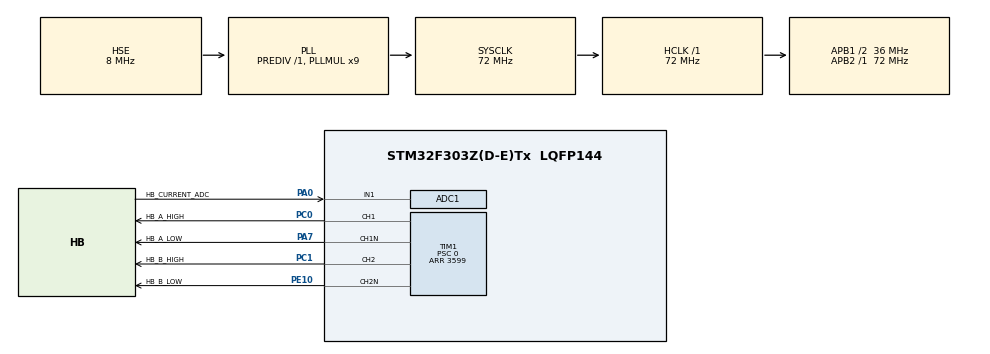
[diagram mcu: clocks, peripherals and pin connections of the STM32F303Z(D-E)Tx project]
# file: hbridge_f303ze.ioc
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# Reconstructed STM32F303ZE H-bridge profile. CubeMX GUI Generate Code has not been run.
# The checked-in HAL initialization and ARM ELF build are verified separately.
# PC0/PA7=left high/low; PC1/PE10=right high/low; PA0=current ADC.
# Driver EN is tied high on the supplied PCB. Do not add a fictional EN GPIO.
ADC1.Channel-0\#ChannelRegularConversion=ADC_CHANNEL_1
ADC1.ClockPrescaler=ADC_CLOCK_SYNC_PCLK_DIV2
ADC1.ContinuousConvMode=DISABLE
ADC1.DMAContinuousRequests=DISABLE
ADC1.DataAlign=ADC_DATAALIGN_RIGHT
ADC1.DiscontinuousConvMode=DISABLE
ADC1.EOCSelection=ADC_EOC_SINGLE_CONV
ADC1.ExternalTrigConv=ADC_EXTERNALTRIGCONV_T1_TRGO
ADC1.ExternalTrigConvEdge=ADC_EXTERNALTRIGCONVEDGE_RISING
ADC1.LowPowerAutoWait=DISABLE
ADC1.NbrOfConversion=1
ADC1.NbrOfConversionFlag=1
ADC1.Offset-0\#ChannelRegularConversion=0
ADC1.OffsetNumber-0\#ChannelRegularConversion=ADC_OFFSET_NONE
ADC1.Overrun=ADC_OVR_DATA_PRESERVED
ADC1.Rank-0\#ChannelRegularConversion=1
ADC1.Resolution=ADC_RESOLUTION_12B
ADC1.SamplingTime-0\#ChannelRegularConversion=ADC_SAMPLETIME_19CYCLES_5
ADC1.ScanConvMode=ADC_SCAN_DISABLE
ADC1.master=1
Mcu.Family=STM32F3
Mcu.Name=STM32F303Z(D-E)Tx
Mcu.Package=LQFP144
NVIC.ADC1_2_IRQn=true\:1\:0\:false\:false\:true\:true\:true\:true
NVIC.PriorityGroup=NVIC_PRIORITYGROUP_4
PA0.GPIO_Label=HB_CURRENT_ADC
PA0.Mode=IN1-Single-Ended
PA0.Signal=ADC1_IN1
PA13.Mode=Serial_Wire
PA13.Signal=SYS_JTMS-SWDIO
PA14.Mode=Serial_Wire
PA14.Signal=SYS_JTCK-SWCLK
PF0-OSC_IN.Mode=HSE-External-Clock-Source
PF0-OSC_IN.Signal=RCC_OSC_IN
ProjectManager.HeapSize=0x0
ProjectManager.StackSize=0x1000
ProjectManager.TargetToolchain=STM32CubeIDE
RCC.AHBFreq_Value=72000000
RCC.APB1CLKDivider=RCC_HCLK_DIV2
RCC.APB1Freq_Value=36000000
RCC.APB1TimFreq_Value=72000000
RCC.APB2Freq_Value=72000000
RCC.APB2CLKDivider=RCC_HCLK_DIV1
RCC.APB2TimFreq_Value=72000000
RCC.CortexFreq_Value=72000000
RCC.HCLKFreq_Value=72000000
RCC.HSE_VALUE=8000000
RCC.HSI_VALUE=8000000
RCC.PLLMUL=RCC_PLL_MUL9
RCC.PLLSourceVirtual=RCC_PLLSOURCE_HSE
RCC.PREDIV=RCC_PREDIV_DIV1
RCC.SYSCLKFreq_VALUE=72000000
RCC.SYSCLKSourceVirtual=RCC_SYSCLKSOURCE_PLLCLK
RCC.TIM1SW=RCC_TIM1CLK_HCLK
TIM1.AutoReloadPreload=TIM_AUTORELOAD_PRELOAD_ENABLE
TIM1.AutomaticOutput=TIM_AUTOMATICOUTPUT_DISABLE
TIM1.Break2Filter=0
TIM1.Break2Polarity=TIM_BREAK2POLARITY_HIGH
TIM1.Break2State=TIM_BREAK2_DISABLE
TIM1.BreakFilter=0
TIM1.BreakPolarity=TIM_BREAKPOLARITY_HIGH
TIM1.BreakState=TIM_BREAK_DISABLE
TIM1.ClockDivision=TIM_CLOCKDIVISION_DIV1
TIM1.CounterMode=TIM_COUNTERMODE_UP
TIM1.DeadTime=72
TIM1.LockLevel=TIM_LOCKLEVEL_OFF
TIM1.OffStateIDLEMode=TIM_OSSI_ENABLE
TIM1.OffStateRunMode=TIM_OSSR_ENABLE
TIM1.Period=3599
TIM1.Prescaler=0
TIM1.RepetitionCounter=0
TIM1.TIM_MasterOutputTrigger=TIM_TRGO_OC4REF
TIM1.TIM_MasterOutputTrigger2=TIM_TRGO2_RESET
TIM1.TIM_MasterSlaveMode=TIM_MASTERSLAVEMODE_DISABLE
VP_TIM1_VS_ClockSourceINT.Mode=Internal
VP_TIM1_VS_no_output4.Mode=PWM Generation4 No Output
board=NUCLEO-F303ZE
PA7.GPIO_Label=HB_A_LOW
PA7.GPIO_PuPd=GPIO_PULLDOWN
PA7.GPIO_Speed=GPIO_SPEED_FREQ_HIGH
PA7.Mode=PWM Generation1 CH1 CH1N
PA7.Signal=TIM1_CH1N
PC0.GPIO_Label=HB_A_HIGH
PC0.GPIO_PuPd=GPIO_PULLDOWN
PC0.GPIO_Speed=GPIO_SPEED_FREQ_HIGH
PC0.Mode=PWM Generation1 CH1 CH1N
PC0.Signal=S_TIM1_CH1
SH.S_TIM1_CH1.0=TIM1_CH1,PWM Generation1 CH1 CH1N
PE10.GPIO_Label=HB_B_LOW
PE10.GPIO_PuPd=GPIO_PULLDOWN
PE10.GPIO_Speed=GPIO_SPEED_FREQ_HIGH
PE10.Mode=PWM Generation2 CH2 CH2N
PE10.Signal=TIM1_CH2N
PC1.GPIO_Label=HB_B_HIGH
PC1.GPIO_PuPd=GPIO_PULLDOWN
PC1.GPIO_Speed=GPIO_SPEED_FREQ_HIGH
PC1.Mode=PWM Generation2 CH2 CH2N
PC1.Signal=S_TIM1_CH2
SH.S_TIM1_CH2.0=TIM1_CH2,PWM Generation2 CH2 CH2N
TIM1.Channel-PWM\ Generation1\ CH1\ CH1N=TIM_CHANNEL_1
TIM1.OCMode_PWM-PWM\ Generation1\ CH1\ CH1N=TIM_OCMODE_PWM1
TIM1.Pulse-PWM\ Generation1\ CH1\ CH1N=0
TIM1.OCFastMode_PWM-PWM\ Generation1\ CH1\ CH1N=TIM_OCFAST_DISABLE
TIM1.OCPolarity_1=TIM_OCPOLARITY_HIGH
TIM1.OCNPolarity_1=TIM_OCNPOLARITY_HIGH
TIM1.OCIdleState_1=TIM_OCIDLESTATE_RESET
TIM1.OCNIdleState_1=TIM_OCNIDLESTATE_RESET
TIM1.Channel-PWM\ Generation2\ CH2\ CH2N=TIM_CHANNEL_2
TIM1.OCMode_PWM-PWM\ Generation2\ CH2\ CH2N=TIM_OCMODE_PWM1
TIM1.Pulse-PWM\ Generation2\ CH2\ CH2N=0
TIM1.OCFastMode_PWM-PWM\ Generation2\ CH2\ CH2N=TIM_OCFAST_DISABLE
TIM1.OCPolarity_2=TIM_OCPOLARITY_HIGH
TIM1.OCNPolarity_2=TIM_OCNPOLARITY_HIGH
TIM1.OCIdleState_2=TIM_OCIDLESTATE_RESET
TIM1.OCNIdleState_2=TIM_OCNIDLESTATE_RESET
TIM1.Channel-PWM\ Generation4\ No\ Output=TIM_CHANNEL_4
TIM1.OCMode_PWM-PWM\ Generation4\ No\ Output=TIM_OCMODE_PWM2
TIM1.Pulse-PWM\ Generation4\ No\ Output=2700
TIM1.OCFastMode_PWM-PWM\ Generation4\ No\ Output=TIM_OCFAST_DISABLE

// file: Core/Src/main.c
/* Standalone HAL initialization reference for NUCLEO-F303ZE.
 * hbridge_f303ze.ioc describes the same configuration; it has not been run
 * through CubeMX GUI generation. Keep the USER CODE calls when regenerating.
 */
#include "main.h"
/* USER CODE BEGIN Includes */
#include "hb_app.h"
/* USER CODE END Includes */

ADC_HandleTypeDef hadc1;
TIM_HandleTypeDef htim1;
static void MX_GPIO_Init(void);
static void MX_ADC1_Init(void);
static void MX_TIM1_Init(void);

int main(void)
{
    HAL_Init();
    SystemClock_Config();
    MX_GPIO_Init();
    MX_ADC1_Init();
    MX_TIM1_Init();
    /* USER CODE BEGIN 2 */
    HB_App_Init();
    /* USER CODE END 2 */
    while (1) {
        /* USER CODE BEGIN 3 */
        HB_App_Poll();
        /* USER CODE END 3 */
    }
}

void SystemClock_Config(void)
{
    /* ST-LINK의 8 MHz 외부 클럭을 PLL x9로 올려 MCU/TIM1을 72 MHz로 설정합니다. */
    RCC_OscInitTypeDef osc = {0};
    RCC_ClkInitTypeDef clocks = {0};
    RCC_PeriphCLKInitTypeDef peripheral = {0};
    osc.OscillatorType = RCC_OSCILLATORTYPE_HSE;
    osc.HSEState = RCC_HSE_BYPASS;
    osc.PLL.PREDIV = RCC_PREDIV_DIV1;
    osc.PLL.PLLState = RCC_PLL_ON;
    osc.PLL.PLLSource = RCC_PLLSOURCE_HSE;
    osc.PLL.PLLMUL = RCC_PLL_MUL9;
    if (HAL_RCC_OscConfig(&osc) != HAL_OK) Error_Handler();
    clocks.ClockType = RCC_CLOCKTYPE_HCLK | RCC_CLOCKTYPE_SYSCLK |
                       RCC_CLOCKTYPE_PCLK1 | RCC_CLOCKTYPE_PCLK2;
    clocks.SYSCLKSource = RCC_SYSCLKSOURCE_PLLCLK;
    clocks.AHBCLKDivider = RCC_SYSCLK_DIV1;
    clocks.APB1CLKDivider = RCC_HCLK_DIV2;
    clocks.APB2CLKDivider = RCC_HCLK_DIV1;
    if (HAL_RCC_ClockConfig(&clocks, FLASH_LATENCY_2) != HAL_OK) Error_Handler();
    /* Explicitly avoid the alternate PLL x2 TIM1 clock path. */
    peripheral.PeriphClockSelection = RCC_PERIPHCLK_TIM1;
    peripheral.Tim1ClockSelection = RCC_TIM1CLK_HCLK;
    if (HAL_RCCEx_PeriphCLKConfig(&peripheral) != HAL_OK) Error_Handler();
}

static void MX_GPIO_Init(void)
{
    GPIO_InitTypeDef gpio = {0};
    __HAL_RCC_GPIOA_CLK_ENABLE();
    __HAL_RCC_GPIOC_CLK_ENABLE();
    __HAL_RCC_GPIOE_CLK_ENABLE();
    /* All four driver inputs are low before assigning the timer AF. */
    HAL_GPIO_WritePin(GPIOA, HB_GATE_GPIOA_PINS, GPIO_PIN_RESET);
    HAL_GPIO_WritePin(GPIOC, HB_GATE_GPIOC_PINS, GPIO_PIN_RESET);
    HAL_GPIO_WritePin(GPIOE, HB_GATE_GPIOE_PINS, GPIO_PIN_RESET);
    gpio.Mode = GPIO_MODE_OUTPUT_PP;
    gpio.Pull = GPIO_PULLDOWN;
    gpio.Speed = GPIO_SPEED_FREQ_HIGH;
    gpio.Pin = HB_GATE_GPIOA_PINS;
    HAL_GPIO_Init(GPIOA, &gpio);
    gpio.Pin = HB_GATE_GPIOC_PINS;
    HAL_GPIO_Init(GPIOC, &gpio);
    gpio.Pin = HB_GATE_GPIOE_PINS;
    HAL_GPIO_Init(GPIOE, &gpio);
}

static void MX_ADC1_Init(void)
{
    /* PA0의 센서 전압을 12 bit로 변환합니다. 연속 자유 변환 대신 TIM1 TRGO마다 한 번 측정합니다. */
    ADC_MultiModeTypeDef multi = {0};
    ADC_ChannelConfTypeDef channel = {0};
    hadc1.Instance = ADC1;
    hadc1.Init.ClockPrescaler = ADC_CLOCK_SYNC_PCLK_DIV2;
    hadc1.Init.Resolution = ADC_RESOLUTION_12B;
    hadc1.Init.ScanConvMode = ADC_SCAN_DISABLE;
    hadc1.Init.ContinuousConvMode = DISABLE;
    hadc1.Init.DiscontinuousConvMode = DISABLE;
    hadc1.Init.ExternalTrigConvEdge = ADC_EXTERNALTRIGCONVEDGE_RISING;
    hadc1.Init.ExternalTrigConv = ADC_EXTERNALTRIGCONV_T1_TRGO;
    hadc1.Init.DataAlign = ADC_DATAALIGN_RIGHT;
    hadc1.Init.NbrOfConversion = 1U;
    hadc1.Init.DMAContinuousRequests = DISABLE;
    hadc1.Init.EOCSelection = ADC_EOC_SINGLE_CONV;
    hadc1.Init.LowPowerAutoWait = DISABLE;
    hadc1.Init.Overrun = ADC_OVR_DATA_PRESERVED;
    if (HAL_ADC_Init(&hadc1) != HAL_OK) Error_Handler();
    multi.Mode = ADC_MODE_INDEPENDENT;
    if (HAL_ADCEx_MultiModeConfigChannel(&hadc1, &multi) != HAL_OK) Error_Handler();
    channel.Channel = ADC_CHANNEL_1;
    channel.Rank = ADC_REGULAR_RANK_1;
    channel.SingleDiff = ADC_SINGLE_ENDED;
    channel.SamplingTime = ADC_SAMPLETIME_19CYCLES_5;
    channel.OffsetNumber = ADC_OFFSET_NONE;
    channel.Offset = 0U;
    if (HAL_ADC_ConfigChannel(&hadc1, &channel) != HAL_OK) Error_Handler();
}

static void MX_TIM1_Init(void)
{
    /* PSC=0, ARR=3599: 72 MHz/3600=20 kHz. CH1/CH2는 상/하측 상보 출력입니다. */
    TIM_ClockConfigTypeDef clock = {0};
    TIM_MasterConfigTypeDef master = {0};
    TIM_OC_InitTypeDef output = {0};
    TIM_BreakDeadTimeConfigTypeDef safety = {0};
    htim1.Instance = TIM1;
    htim1.Init.Prescaler = 0U;
    htim1.Init.CounterMode = TIM_COUNTERMODE_UP;
    htim1.Init.Period = HB_PWM_PERIOD_COUNTS - 1U;
    htim1.Init.ClockDivision = TIM_CLOCKDIVISION_DIV1;
    htim1.Init.RepetitionCounter = 0U;
    htim1.Init.AutoReloadPreload = TIM_AUTORELOAD_PRELOAD_ENABLE;
    if (HAL_TIM_Base_Init(&htim1) != HAL_OK) Error_Handler();
    clock.ClockSource = TIM_CLOCKSOURCE_INTERNAL;
    if (HAL_TIM_ConfigClockSource(&htim1, &clock) != HAL_OK) Error_Handler();
    if (HAL_TIM_PWM_Init(&htim1) != HAL_OK) Error_Handler();
    master.MasterOutputTrigger = TIM_TRGO_OC4REF;
    master.MasterOutputTrigger2 = TIM_TRGO2_RESET;
    master.MasterSlaveMode = TIM_MASTERSLAVEMODE_DISABLE;
    if (HAL_TIMEx_MasterConfigSynchronization(&htim1, &master) != HAL_OK) Error_Handler();

    output.OCMode = TIM_OCMODE_PWM1;
    output.Pulse = 0U;
    output.OCPolarity = TIM_OCPOLARITY_HIGH;
    output.OCNPolarity = TIM_OCNPOLARITY_HIGH;
    output.OCFastMode = TIM_OCFAST_DISABLE;
    output.OCIdleState = TIM_OCIDLESTATE_RESET;
    output.OCNIdleState = TIM_OCNIDLESTATE_RESET;
    if (HAL_TIM_PWM_ConfigChannel(&htim1, &output, TIM_CHANNEL_1) != HAL_OK) Error_Handler();
    if (HAL_TIM_PWM_ConfigChannel(&htim1, &output, TIM_CHANNEL_2) != HAL_OK) Error_Handler();
    output.OCMode = TIM_OCMODE_PWM2;
    /* CH4는 외부 핀 없이 주기 시작 후 37.5 us에 ADC를 시작하는 내부 신호입니다. */
    output.Pulse = HB_ADC_SAMPLE_COMPARE;
    if (HAL_TIM_PWM_ConfigChannel(&htim1, &output, TIM_CHANNEL_4) != HAL_OK) Error_Handler();

    safety.OffStateRunMode = TIM_OSSR_ENABLE;
    safety.OffStateIDLEMode = TIM_OSSI_ENABLE;
    safety.LockLevel = TIM_LOCKLEVEL_OFF;
    safety.DeadTime = HB_DEADTIME_TICKS; /* 상/하측 모두 OFF인 전환 간격. 현재 72 ticks=1 us. */
    safety.BreakState = TIM_BREAK_DISABLE;
    safety.BreakPolarity = TIM_BREAKPOLARITY_HIGH;
    safety.BreakFilter = 0U;
    safety.Break2State = TIM_BREAK2_DISABLE;
    safety.Break2Polarity = TIM_BREAK2POLARITY_HIGH;
    safety.Break2Filter = 0U;
    safety.AutomaticOutput = TIM_AUTOMATICOUTPUT_DISABLE;
    if (HAL_TIMEx_ConfigBreakDeadTime(&htim1, &safety) != HAL_OK) Error_Handler();
    CLEAR_BIT(TIM1->BDTR, TIM_BDTR_MOE); /* 초기화만으로 모터가 켜지지 않게 출력은 차단합니다. */
    HAL_TIM_MspPostInit(&htim1);
    /* No HAL_TIM_PWM_Start here: it would set MOE. HB_App starts the
     * counter with HAL_TIM_Base_Start and owns every output transition. */
}

void Error_Handler(void)
{
    HB_App_EmergencyStop();
    __disable_irq();
    while (1) { }
}
